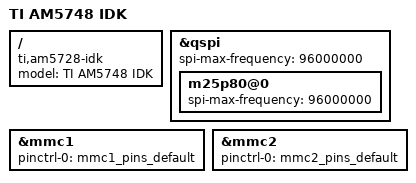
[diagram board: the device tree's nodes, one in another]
/*
 * Copyright (C) 2015-2016 Texas Instruments Incorporated - http://www.ti.com/
 *
 * This program is free software; you can redistribute it and/or modify
 * it under the terms of the GNU General Public License version 2 as
 * published by the Free Software Foundation.
 */

/dts-v1/;

#include "dra74x-p.dtsi"
#include "am572x-idk-common.dtsi"

/ {
	model = "TI AM5748 IDK";
	compatible = "ti,am5728-idk", "ti,dra762", "ti,dra7";
};

&qspi {
	spi-max-frequency = <96000000>;
	m25p80@0 {
		spi-max-frequency = <96000000>;
	};
};

&mmc1 {
	pinctrl-names = "default";
	pinctrl-0 = <&mmc1_pins_default>;
	/delete-property/ sd-uhs-sdr104;
	/delete-property/ sd-uhs-sdr50;
	/delete-property/ sd-uhs-ddr50;
	/delete-property/ sd-uhs-sdr25;
	/delete-property/ sd-uhs-sdr12;
};

&mmc2 {
	pinctrl-names = "default";
	pinctrl-0 = <&mmc2_pins_default>;
};
